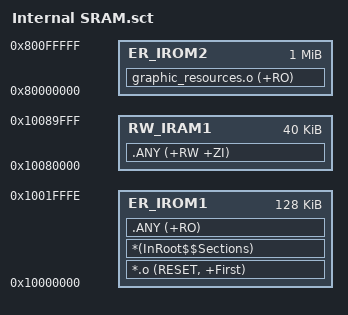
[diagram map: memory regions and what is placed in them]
; *************************************************************
; *** Scatter-Loading Description File generated by uVision ***
; *************************************************************

LR_IROM1 0x10000000 0x8001FFFF  {    ; load region size_region
  ER_IROM1 0x10000000 0x0001FFFF  {  ; load address = execution address
   *.o (RESET, +First)
   *(InRoot$$Sections)
   .ANY (+RO)
  }
  RW_IRAM1 0x10080000 0x0000A000  {  ; RW data
   .ANY (+RW +ZI)
  }
}

LR_IROM2 0x80000000 0x00100000   {  ; load region for SPIFI data
  ER_IROM2 0x80000000 0x00100000  {  ; Image data to be loaded into SPIFI
   graphic_resources.o (+RO)
  }
}
